# STM32N647xx register map
File version: 1.0
Registers are 32-bit, read-write, reset 0x0 unless marked. A register's access mark holds for its fields unless they carry their own. Offsets are from the block's base; [hi:lo] are bit positions; {n}, {i} and the like mark numbered series.

## GPIOA — General Purpose I/O
Base 0x46020000
Same registers: GPIOB 0x46020400, GPIOC 0x46020800, GPIOD 0x46020C00, GPIOE 0x46021000, GPIOF 0x46021400, GPIOG 0x46021800, GPIOH 0x46021C00, GPION 0x46023400, GPIOO 0x46023800, GPIOP 0x46023C00, GPIOQ 0x46024000
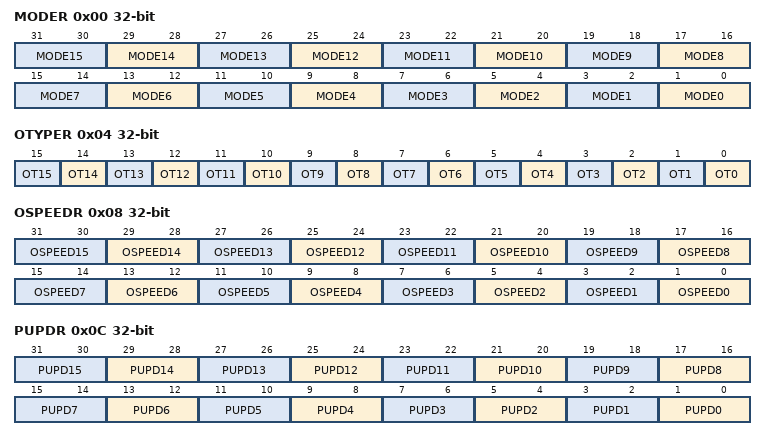
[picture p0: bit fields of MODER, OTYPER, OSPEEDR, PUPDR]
0x00 MODER — GPIO port mode register
  [2n+1:2n] MODE{n} (n=0..15)
0x04 OTYPER — GPIO port output type register
  [n] OT{n} (n=0..15)
0x08 OSPEEDR — GPIO port output speed register
  [2n+1:2n] OSPEED{n} (n=0..15)
0x0C PUPDR — GPIO port pull-up/pull-down register
  [2n+1:2n] PUPD{n} (n=0..15)
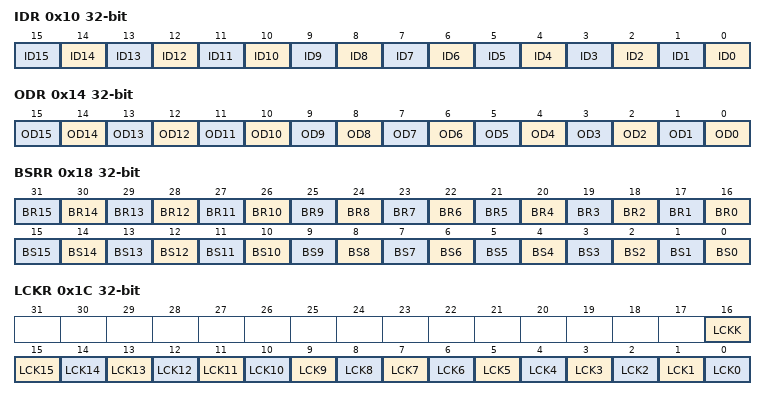
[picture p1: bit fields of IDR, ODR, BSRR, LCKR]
0x10 IDR — GPIO port input data register
  [n] ID{n} (n=0..15)
0x14 ODR — GPIO port output data register
  [n] OD{n} (n=0..15)
0x18 BSRR — GPIO port bit set/reset register
  [n+16] BR{n} (n=0..15), [n] BS{n} (n=0..15)
0x1C LCKR — GPIO port configuration lock register
  [16] LCKK, [n] LCK{n} (n=0..15)
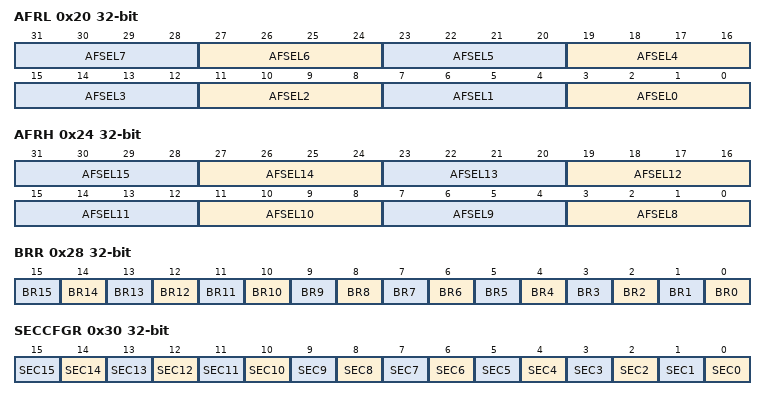
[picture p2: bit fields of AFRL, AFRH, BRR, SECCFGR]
0x20 AFRL — GPIO alternate function registers
  [4n+3:4n] AFSEL{n} (n=0..7)
0x24 AFRH — GPIO alternate function registers
  [4n-29:4n-32] AFSEL{n} (n=8..15)
0x28 BRR — GPIO bit reset register
  [n] BR{n} (n=0..15)
0x30 SECCFGR — GPIO port secure configuration register
  [n] SEC{n} (n=0..15)
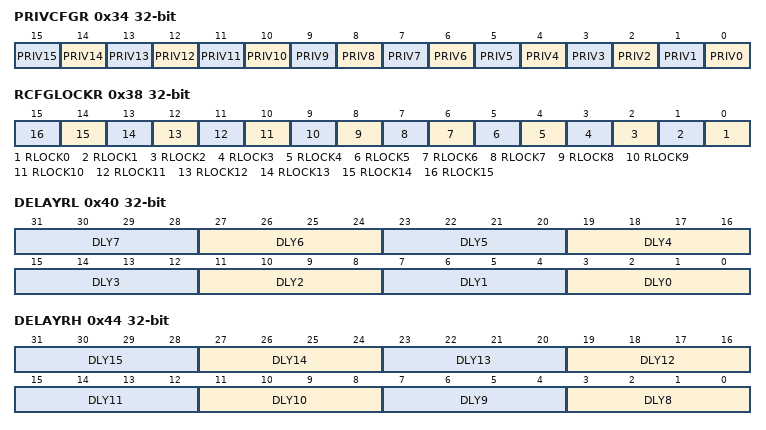
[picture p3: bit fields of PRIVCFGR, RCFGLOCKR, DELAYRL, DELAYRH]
0x34 PRIVCFGR — GPIO port privileged configuration register
  [n] PRIV{n} (n=0..15)
0x38 RCFGLOCKR — GPIO port resource configuration register
  [n] RLOCK{n} (n=0..15)
0x40 DELAYRL — GPIO port delay register
  [4n+3:4n] DLY{n} (n=0..7)
0x44 DELAYRH — GPIO port delay register
  [4n-29:4n-32] DLY{n} (n=8..15)
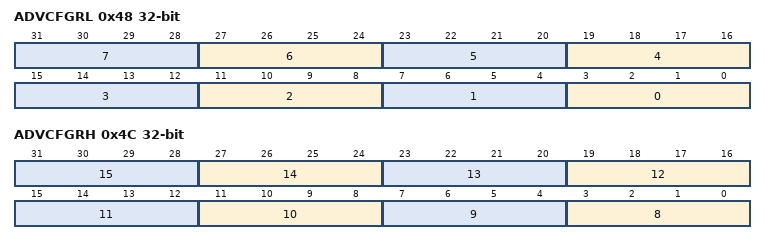
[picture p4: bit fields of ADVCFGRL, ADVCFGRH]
0x48 ADVCFGRL — GPIO port advanced configuration register
  [4n+3:4n] {n} (n=0..7)
0x4C ADVCFGRH — GPIO port advanced configuration register
  [4n-29:4n-32] {n} (n=8..15)

## CRC — CRC calculation unit
Base 0x46024C00
0x00 DR — CRC Data register
  [31:0] DR — Data register bits
0x04 IDR — CRC Independent data register
  [31:0] IDR — General-purpose 32-bits data register bits
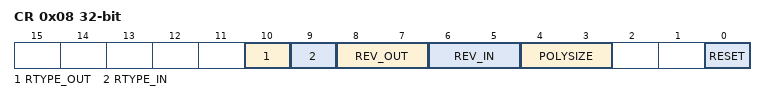
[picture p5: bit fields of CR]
0x08 CR — CRC Control register
  [10] RTYPE_OUT — Reverse type output
    0=BIT (Output Data reverse type at bit level granularity); 1=BYTE_HALFWORD (Output Data reverse type at byte or half-word level granularity)
  [9] RTYPE_IN — Reverse type input
    0=BIT (Input Data reverse type at bit level granularity); 1=BYTE_HALFWORD (Input Data reverse type at byte or half-word level granularity)
  [8:7] REV_OUT — REV_OUT Reverse Output Data bits
  [6:5] REV_IN — REV_IN Reverse Input Data bits
  [4:3] POLYSIZE — Polynomial size bits
    0=POLYLENGTH_32B (32 bits Polynomial size); 1=POLYLENGTH_16B (16 bits Polynomial size); 2=POLYLENGTH_8B (8 bits Polynomial size); 3=POLYLENGTH_7B (7 bits Polynomial size)
  [0] RESET — RESET the CRC computation unit bit
0x10 INIT — Initial CRC value register
  [31:0] INIT — Initial CRC value bits
0x14 POL — CRC polynomial register
  [31:0] POL — Coefficients of the polynomial

## GFXTIM
Base 0x48004000
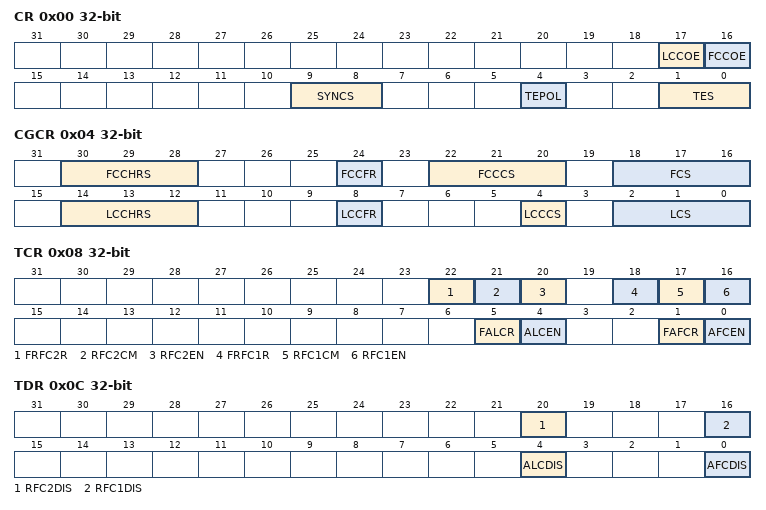
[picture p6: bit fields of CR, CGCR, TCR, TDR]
0x00 CR — GFXTIM configuration register
  [17] LCCOE, [16] FCCOE, [9:8] SYNCS, [4] TEPOL, [1:0] TES
0x04 CGCR — GFXTIM clock generator configuration register
  [30:28] FCCHRS, [24] FCCFR, [22:20] FCCCS, [18:16] FCS, [14:12] LCCHRS, [8] LCCFR, [4] LCCCS, [2:0] LCS
0x08 TCR — GFXTIM timers configuration register
  [22] FRFC2R, [21] RFC2CM, [20] RFC2EN, [18] FRFC1R, [17] RFC1CM, [16] RFC1EN, [5] FALCR, [4] ALCEN, [1] FAFCR, [0] AFCEN
0x0C TDR — GFXTIM timers disable register
  [20] RFC2DIS, [16] RFC1DIS, [4] ALCDIS, [0] AFCDIS
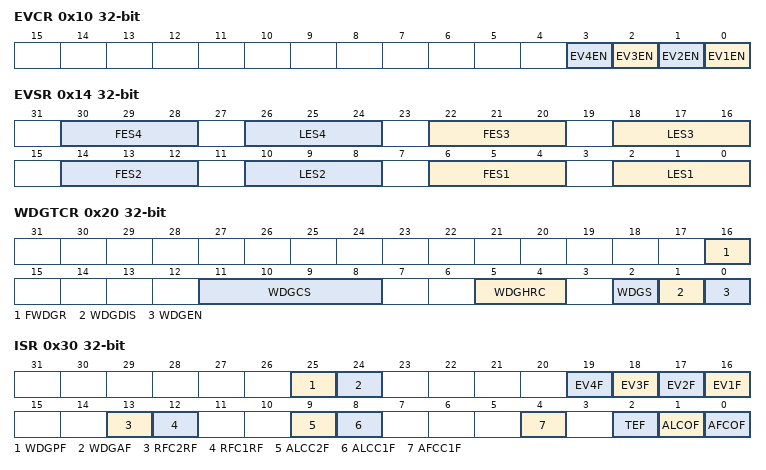
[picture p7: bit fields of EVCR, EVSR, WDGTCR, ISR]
0x10 EVCR — GFXTIM events control register
  [n-1] EV{n}EN (n=1..4)
0x14 EVSR — GFXTIM events selection register
  [8n-2:8n-4] FES{n} (n=1..4), [8n-6:8n-8] LES{n} (n=1..4)
0x20 WDGTCR — GFXTIM watchdog timer configuration register
  [16] FWDGR, [11:8] WDGCS, [5:4] WDGHRC, [2] WDGS, [1] WDGDIS, [0] WDGEN
0x30 ISR — GFXTIM interrupt status register
  [25] WDGPF, [24] WDGAF, [n+15] EV{n}F (n=1..4), [13] RFC2RF, [12] RFC1RF, [9] ALCC2F, [8] ALCC1F, [4] AFCC1F, [2] TEF, [1] ALCOF, [0] AFCOF
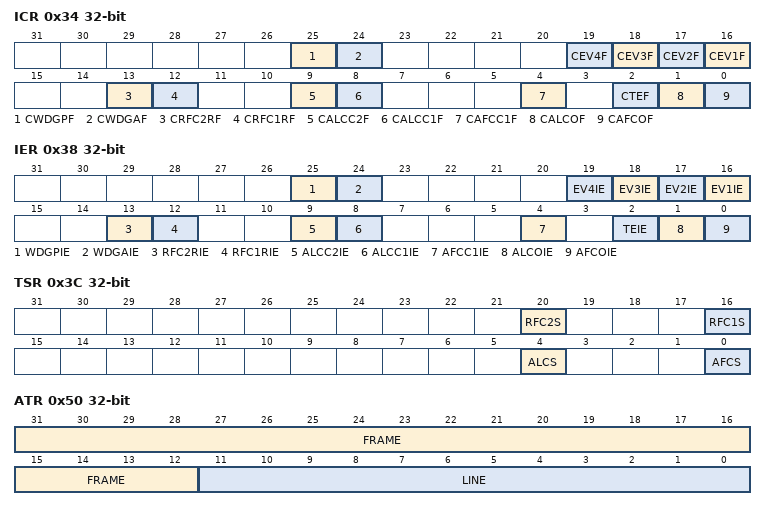
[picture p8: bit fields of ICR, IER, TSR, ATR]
0x34 ICR — GFXTIM interrupt clear register
  [25] CWDGPF, [24] CWDGAF, [n+15] CEV{n}F (n=1..4), [13] CRFC2RF, [12] CRFC1RF, [9] CALCC2F, [8] CALCC1F, [4] CAFCC1F, [2] CTEF, [1] CALCOF, [0] CAFCOF
0x38 IER — GFXTIM interrupt enable register
  [25] WDGPIE, [24] WDGAIE, [n+15] EV{n}IE (n=1..4), [13] RFC2RIE, [12] RFC1RIE, [9] ALCC2IE, [8] ALCC1IE, [4] AFCC1IE, [2] TEIE, [1] ALCOIE, [0] AFCOIE
0x3C TSR — GFXTIM timers status register
  [20] RFC2S, [16] RFC1S, [4] ALCS, [0] AFCS
0x40 LCCRR — GFXTIM line clock counter reload register
  [21:0] RELOAD
0x44 FCCRR — GFXTIM frame clock counter reload register
  [11:0] RELOAD
0x50 ATR — GFXTIM absolute time register
  [31:12] FRAME, [11:0] LINE
0x54 AFCR — GFXTIM absolute frame counter register
  [19:0] FRAME
0x58 ALCR — GFXTIM absolute line counter register
  [11:0] LINE
0x60 AFCC1R — GFXTIM absolute frame counter compare 1 register
  [19:0] FRAME
0x70 ALCC1R — GFXTIM absolute line counter compare 1 register
  [11:0] LINE
0x74 ALCC2R — GFXTIM absolute line counter compare 2 register
  [11:0] LINE
0x80 RFC1R — GFXTIM relative frame counter 1 register
  [11:0] FRAME
0x84 RFC1RR — GFXTIM relative frame counter 1 reload register
  [11:0] FRAME
0x88 RFC2R — GFXTIM relative frame counter 2 register
  [11:0] FRAME
0x8C RFC2RR — GFXTIM relative frame counter 2 reload register
  [11:0] FRAME
0xA0 WDGCR — GFXTIM watchdog counter register
  [15:0] VALUE
0xA4 WDGRR — GFXTIM watchdog reload register
  [15:0] RELOAD
0xA8 WDGPAR — GFXTIM watchdog pre-alarm register
  [15:0] PREALARM
0x3F0 HWCFGR — GFXTIM HW configuration register
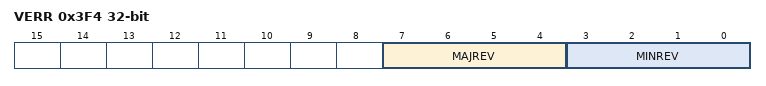
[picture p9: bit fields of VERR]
0x3F4 VERR — GFXTIM version register
  [7:4] MAJREV, [3:0] MINREV
0x3F8 IPIDR — GFXTIM identification register
  [31:0] ID
0x3FC SIDR — GFXTIM size identification register
  [31:0] SID
